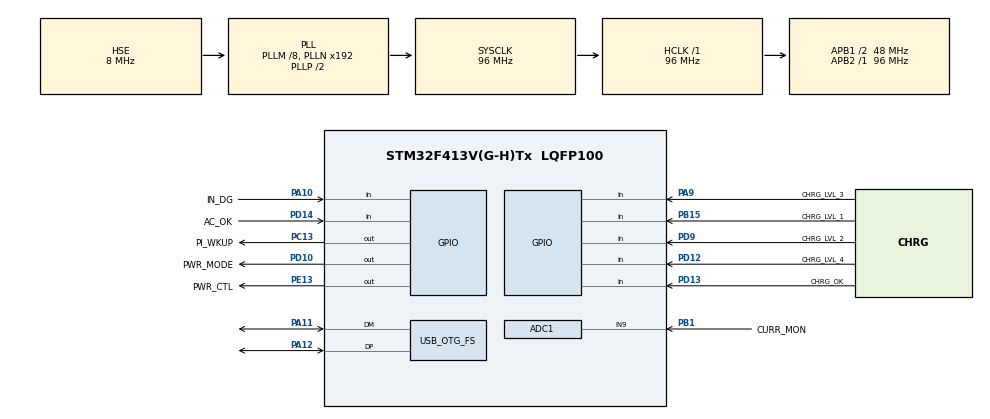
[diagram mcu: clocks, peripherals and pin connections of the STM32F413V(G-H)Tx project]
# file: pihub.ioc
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ADC1.Channel-0\#ChannelRegularConversion=ADC_CHANNEL_9
ADC1.NbrOfConversionFlag=1
ADC1.Rank-0\#ChannelRegularConversion=1
ADC1.SamplingTime-0\#ChannelRegularConversion=ADC_SAMPLETIME_3CYCLES
ADC1.master=1
Mcu.Family=STM32F4
Mcu.Name=STM32F413V(G-H)Tx
Mcu.Package=LQFP100
NVIC.OTG_FS_IRQn=true\:0\:0\:false\:false\:true\:false\:true
NVIC.PriorityGroup=NVIC_PRIORITYGROUP_4
PA10.GPIO_Label=IN_DG
PA10.GPIO_PuPd=GPIO_PULLDOWN
PA10.Signal=GPIO_Input
PA11.Mode=Device_Only
PA11.Signal=USB_OTG_FS_DM
PA12.Mode=Device_Only
PA12.Signal=USB_OTG_FS_DP
PA9.GPIO_Label=CHRG_LVL_3
PA9.GPIO_PuPd=GPIO_PULLUP
PA9.Signal=GPIO_Input
PB1.GPIO_Label=CURR_MON
PB1.Signal=SharedAnalog_PB1
PB15.GPIO_Label=CHRG_LVL_1
PB15.GPIO_PuPd=GPIO_PULLUP
PB15.Signal=GPIO_Input
PC13.GPIO_Label=PI_WKUP
PC13.GPIO_ModeDefaultOutputPP=GPIO_MODE_OUTPUT_OD
PC13.GPIO_PuPd=GPIO_PULLUP
PC13.PinState=GPIO_PIN_SET
PC13.Signal=GPIO_Output
PC14-OSC32_IN.Mode=LSE-External-Oscillator
PC14-OSC32_IN.Signal=RCC_OSC32_IN
PC15-OSC32_OUT.Mode=LSE-External-Oscillator
PC15-OSC32_OUT.Signal=RCC_OSC32_OUT
PD10.GPIO_Label=PWR_MODE
PD10.GPIO_ModeDefaultOutputPP=GPIO_MODE_OUTPUT_PP
PD10.GPIO_PuPd=GPIO_NOPULL
PD10.Signal=GPIO_Output
PD12.GPIO_Label=CHRG_LVL_4
PD12.GPIO_PuPd=GPIO_PULLUP
PD12.Signal=GPIO_Input
PD13.GPIO_Label=CHRG_OK
PD13.GPIO_PuPd=GPIO_PULLUP
PD13.Signal=GPIO_Input
PD14.GPIO_Label=AC_OK
PD14.GPIO_PuPd=GPIO_PULLUP
PD14.Signal=GPIO_Input
PD9.GPIO_Label=CHRG_LVL_2
PD9.GPIO_PuPd=GPIO_PULLUP
PD9.Signal=GPIO_Input
PE13.GPIO_Label=PWR_CTL
PE13.GPIO_ModeDefaultOutputPP=GPIO_MODE_OUTPUT_OD
PE13.GPIO_PuPd=GPIO_NOPULL
PE13.PinState=GPIO_PIN_SET
PE13.Signal=GPIO_Output
PH0\ -\ OSC_IN.Mode=HSE-External-Oscillator
PH0\ -\ OSC_IN.Signal=RCC_OSC_IN
PH1\ -\ OSC_OUT.Mode=HSE-External-Oscillator
PH1\ -\ OSC_OUT.Signal=RCC_OSC_OUT
ProjectManager.HeapSize=0x200
ProjectManager.StackSize=0x400
ProjectManager.TargetToolchain=STM32CubeIDE
RCC.AHBFreq_Value=96000000
RCC.APB1CLKDivider=RCC_HCLK_DIV2
RCC.APB1Freq_Value=48000000
RCC.APB1TimFreq_Value=96000000
RCC.APB2Freq_Value=96000000
RCC.APB2TimFreq_Value=96000000
RCC.CortexFreq_Value=96000000
RCC.HCLKFreq_Value=96000000
RCC.HSE_VALUE=8000000
RCC.PLLM=8
RCC.PLLQ=4
RCC.RCC_RTC_Clock_Source=RCC_RTCCLKSOURCE_LSE
RCC.RCC_RTC_Clock_SourceVirtual=RCC_RTCCLKSOURCE_LSE
RCC.SYSCLKFreq_VALUE=96000000
RCC.SYSCLKSource=RCC_SYSCLKSOURCE_PLLCLK
RCC.USBFreq_Value=48000000
RCC.VCOOutputFreq_Value=192000000
RTC.Date=12
RTC.WeekDay=RTC_WEEKDAY_SATURDAY
RTC.Year=85
SH.SharedAnalog_PB1.0=GPIO_Analog
SH.SharedAnalog_PB1.1=ADC1_IN9,IN9
USB_DEVICE.CLASS_NAME_FS=CDC
USB_DEVICE.PRODUCT_STRING_CDC_FS=PIhub VCP
USB_DEVICE.VirtualMode=Cdc
USB_DEVICE.VirtualModeFS=Cdc_FS
USB_OTG_FS.VirtualMode=Device_Only
VP_RTC_VS_RTC_Activate.Mode=RTC_Enabled
VP_RTC_VS_RTC_Calendar.Mode=RTC_Calendar
VP_USB_DEVICE_VS_USB_DEVICE_CDC_FS.Mode=CDC_FS
board=custom

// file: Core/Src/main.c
/* USER CODE BEGIN Header */
/**
  ******************************************************************************
  * @file           : main.c
  * @brief          : Main program body
  ******************************************************************************
  * @attention
  *
  * Copyright (c) 2022 STMicroelectronics.
  * All rights reserved.
  *
  * This software is licensed under terms that can be found in the LICENSE file
  * in the root directory of this software component.
  * If no LICENSE file comes with this software, it is provided AS-IS.
  *
  ******************************************************************************
  */
/* USER CODE END Header */
#include "main.h"
#include "usb_device.h"

/* USER CODE BEGIN Includes */

#include "io_tester.h"

/* USER CODE END Includes */

ADC_HandleTypeDef hadc1;

RTC_HandleTypeDef hrtc;

void SystemClock_Config(void);
static void MX_GPIO_Init(void);
static void MX_RTC_Init(void);
static void MX_ADC1_Init(void);

int main(void)
{

  /* MCU Configuration--------------------------------------------------------*/

  /* Reset of all peripherals, Initializes the Flash interface and the Systick. */
  HAL_Init();

  /* Configure the system clock */
  SystemClock_Config();

  /* Initialize all configured peripherals */
  MX_GPIO_Init();
  MX_RTC_Init();
  MX_USB_DEVICE_Init();
  MX_ADC1_Init();
  /* USER CODE BEGIN 2 */

  // Turn off buffers, so I/O occurs immediately
  setvbuf(stdin,  NULL, _IONBF, 0);
  setvbuf(stdout, NULL, _IONBF, 0);
  //setvbuf(stderr, NULL, _IONBF, 0);

  /* USER CODE END 2 */

  /* Infinite loop */
  /* USER CODE BEGIN WHILE */
  while (1)
  {
    io_scan();
    /* USER CODE END WHILE */

  }
}

void SystemClock_Config(void)
{
  RCC_OscInitTypeDef RCC_OscInitStruct = {0};
  RCC_ClkInitTypeDef RCC_ClkInitStruct = {0};

  /** Configure the main internal regulator output voltage
  */
  __HAL_RCC_PWR_CLK_ENABLE();
  __HAL_PWR_VOLTAGESCALING_CONFIG(PWR_REGULATOR_VOLTAGE_SCALE1);
  /** Initializes the RCC Oscillators according to the specified parameters
  * in the RCC_OscInitTypeDef structure.
  */
  RCC_OscInitStruct.OscillatorType = RCC_OSCILLATORTYPE_HSE|RCC_OSCILLATORTYPE_LSE;
  RCC_OscInitStruct.HSEState = RCC_HSE_ON;
  RCC_OscInitStruct.LSEState = RCC_LSE_ON;
  RCC_OscInitStruct.PLL.PLLState = RCC_PLL_ON;
  RCC_OscInitStruct.PLL.PLLSource = RCC_PLLSOURCE_HSE;
  RCC_OscInitStruct.PLL.PLLM = 8;
  RCC_OscInitStruct.PLL.PLLN = 192;
  RCC_OscInitStruct.PLL.PLLP = RCC_PLLP_DIV2;
  RCC_OscInitStruct.PLL.PLLQ = 4;
  RCC_OscInitStruct.PLL.PLLR = 2;
  if (HAL_RCC_OscConfig(&RCC_OscInitStruct) != HAL_OK)
  {
    Error_Handler();
  }
  /** Initializes the CPU, AHB and APB buses clocks
  */
  RCC_ClkInitStruct.ClockType = RCC_CLOCKTYPE_HCLK|RCC_CLOCKTYPE_SYSCLK
                              |RCC_CLOCKTYPE_PCLK1|RCC_CLOCKTYPE_PCLK2;
  RCC_ClkInitStruct.SYSCLKSource = RCC_SYSCLKSOURCE_PLLCLK;
  RCC_ClkInitStruct.AHBCLKDivider = RCC_SYSCLK_DIV1;
  RCC_ClkInitStruct.APB1CLKDivider = RCC_HCLK_DIV2;
  RCC_ClkInitStruct.APB2CLKDivider = RCC_HCLK_DIV1;

  if (HAL_RCC_ClockConfig(&RCC_ClkInitStruct, FLASH_LATENCY_3) != HAL_OK)
  {
    Error_Handler();
  }
}

static void MX_ADC1_Init(void)
{

  ADC_ChannelConfTypeDef sConfig = {0};

  /** Configure the global features of the ADC (Clock, Resolution, Data Alignment and number of conversion)
  */
  hadc1.Instance = ADC1;
  hadc1.Init.ClockPrescaler = ADC_CLOCK_SYNC_PCLK_DIV4;
  hadc1.Init.Resolution = ADC_RESOLUTION_12B;
  hadc1.Init.ScanConvMode = DISABLE;
  hadc1.Init.ContinuousConvMode = DISABLE;
  hadc1.Init.DiscontinuousConvMode = DISABLE;
  hadc1.Init.ExternalTrigConvEdge = ADC_EXTERNALTRIGCONVEDGE_NONE;
  hadc1.Init.ExternalTrigConv = ADC_SOFTWARE_START;
  hadc1.Init.DataAlign = ADC_DATAALIGN_RIGHT;
  hadc1.Init.NbrOfConversion = 1;
  hadc1.Init.DMAContinuousRequests = DISABLE;
  hadc1.Init.EOCSelection = ADC_EOC_SINGLE_CONV;
  if (HAL_ADC_Init(&hadc1) != HAL_OK)
  {
    Error_Handler();
  }
  /** Configure for the selected ADC regular channel its corresponding rank in the sequencer and its sample time.
  */
  sConfig.Channel = ADC_CHANNEL_9;
  sConfig.Rank = 1;
  sConfig.SamplingTime = ADC_SAMPLETIME_3CYCLES;
  if (HAL_ADC_ConfigChannel(&hadc1, &sConfig) != HAL_OK)
  {
    Error_Handler();
  }

}

static void MX_RTC_Init(void)
{

  RTC_TimeTypeDef sTime = {0};
  RTC_DateTypeDef sDate = {0};

  /** Initialize RTC Only
  */
  hrtc.Instance = RTC;
  hrtc.Init.HourFormat = RTC_HOURFORMAT_24;
  hrtc.Init.AsynchPrediv = 127;
  hrtc.Init.SynchPrediv = 255;
  hrtc.Init.OutPut = RTC_OUTPUT_DISABLE;
  hrtc.Init.OutPutPolarity = RTC_OUTPUT_POLARITY_HIGH;
  hrtc.Init.OutPutType = RTC_OUTPUT_TYPE_OPENDRAIN;
  if (HAL_RTC_Init(&hrtc) != HAL_OK)
  {
    Error_Handler();
  }

  /** Initialize RTC and set the Time and Date
  */
  sTime.Hours = 0x0;
  sTime.Minutes = 0x0;
  sTime.Seconds = 0x0;
  sTime.DayLightSaving = RTC_DAYLIGHTSAVING_NONE;
  sTime.StoreOperation = RTC_STOREOPERATION_RESET;
  if (HAL_RTC_SetTime(&hrtc, &sTime, RTC_FORMAT_BCD) != HAL_OK)
  {
    Error_Handler();
  }
  sDate.WeekDay = RTC_WEEKDAY_SATURDAY;
  sDate.Month = RTC_MONTH_JANUARY;
  sDate.Date = 0x12;
  sDate.Year = 0x85;

  if (HAL_RTC_SetDate(&hrtc, &sDate, RTC_FORMAT_BCD) != HAL_OK)
  {
    Error_Handler();
  }

}

static void MX_GPIO_Init(void)
{
  GPIO_InitTypeDef GPIO_InitStruct = {0};

  /* GPIO Ports Clock Enable */
  __HAL_RCC_GPIOC_CLK_ENABLE();
  __HAL_RCC_GPIOH_CLK_ENABLE();
  __HAL_RCC_GPIOB_CLK_ENABLE();
  __HAL_RCC_GPIOE_CLK_ENABLE();
  __HAL_RCC_GPIOD_CLK_ENABLE();
  __HAL_RCC_GPIOA_CLK_ENABLE();

  /*Configure GPIO pin Output Level */
  HAL_GPIO_WritePin(PI_WKUP_GPIO_Port, PI_WKUP_Pin, GPIO_PIN_SET);

  /*Configure GPIO pin Output Level */
  HAL_GPIO_WritePin(PWR_CTL_GPIO_Port, PWR_CTL_Pin, GPIO_PIN_SET);

  /*Configure GPIO pin Output Level */
  HAL_GPIO_WritePin(PWR_MODE_GPIO_Port, PWR_MODE_Pin, GPIO_PIN_RESET);

  /*Configure GPIO pin : PI_WKUP_Pin */
  GPIO_InitStruct.Pin = PI_WKUP_Pin;
  GPIO_InitStruct.Mode = GPIO_MODE_OUTPUT_OD;
  GPIO_InitStruct.Pull = GPIO_PULLUP;
  GPIO_InitStruct.Speed = GPIO_SPEED_FREQ_LOW;
  HAL_GPIO_Init(PI_WKUP_GPIO_Port, &GPIO_InitStruct);

  /*Configure GPIO pin : PWR_CTL_Pin */
  GPIO_InitStruct.Pin = PWR_CTL_Pin;
  GPIO_InitStruct.Mode = GPIO_MODE_OUTPUT_OD;
  GPIO_InitStruct.Pull = GPIO_NOPULL;
  GPIO_InitStruct.Speed = GPIO_SPEED_FREQ_LOW;
  HAL_GPIO_Init(PWR_CTL_GPIO_Port, &GPIO_InitStruct);

  /*Configure GPIO pin : CHRG_LVL_1_Pin */
  GPIO_InitStruct.Pin = CHRG_LVL_1_Pin;
  GPIO_InitStruct.Mode = GPIO_MODE_INPUT;
  GPIO_InitStruct.Pull = GPIO_PULLUP;
  HAL_GPIO_Init(CHRG_LVL_1_GPIO_Port, &GPIO_InitStruct);

  /*Configure GPIO pins : CHRG_LVL_2_Pin CHRG_LVL_4_Pin CHRG_OK_Pin AC_OK_Pin */
  GPIO_InitStruct.Pin = CHRG_LVL_2_Pin|CHRG_LVL_4_Pin|CHRG_OK_Pin|AC_OK_Pin;
  GPIO_InitStruct.Mode = GPIO_MODE_INPUT;
  GPIO_InitStruct.Pull = GPIO_PULLUP;
  HAL_GPIO_Init(GPIOD, &GPIO_InitStruct);

  /*Configure GPIO pin : PWR_MODE_Pin */
  GPIO_InitStruct.Pin = PWR_MODE_Pin;
  GPIO_InitStruct.Mode = GPIO_MODE_OUTPUT_PP;
  GPIO_InitStruct.Pull = GPIO_NOPULL;
  GPIO_InitStruct.Speed = GPIO_SPEED_FREQ_LOW;
  HAL_GPIO_Init(PWR_MODE_GPIO_Port, &GPIO_InitStruct);

  /*Configure GPIO pin : CHRG_LVL_3_Pin */
  GPIO_InitStruct.Pin = CHRG_LVL_3_Pin;
  GPIO_InitStruct.Mode = GPIO_MODE_INPUT;
  GPIO_InitStruct.Pull = GPIO_PULLUP;
  HAL_GPIO_Init(CHRG_LVL_3_GPIO_Port, &GPIO_InitStruct);

  /*Configure GPIO pin : IN_DG_Pin */
  GPIO_InitStruct.Pin = IN_DG_Pin;
  GPIO_InitStruct.Mode = GPIO_MODE_INPUT;
  GPIO_InitStruct.Pull = GPIO_PULLDOWN;
  HAL_GPIO_Init(IN_DG_GPIO_Port, &GPIO_InitStruct);

}

void Error_Handler(void)
{
  __disable_irq();
  while (1)
  {
  }
}
